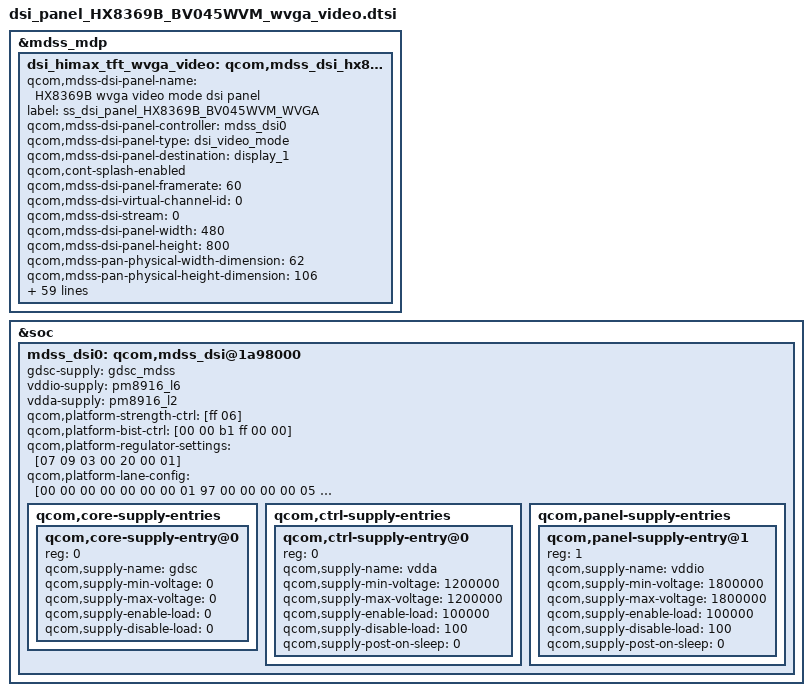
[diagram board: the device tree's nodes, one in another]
/* Copyright (c) 2013-14, Samsung Electronics Corporation. All rights reserved.
 *
 * This program is free software; you can redistribute it and/or modify
 * it under the terms of the GNU General Public License version 2 and
 * only version 2 as published by the Free Software Foundation.
 *
 * This program is distributed in the hope that it will be useful,
 * but WITHOUT ANY WARRANTY; without even the implied warranty of
 * MERCHANTABILITY or FITNESS FOR A PARTICULAR PURPOSE.  See the
 * GNU General Public License for more details.
 */

/*---------------------------------------------------------------------------
 * This file is autogenerated file using gcdb parser. Please do not edit it.
 * Update input XML file to add a new entry or update variable in this file
 * VERSION = "1.0"
 *---------------------------------------------------------------------------*/
&mdss_mdp {
	dsi_himax_tft_wvga_video: qcom,mdss_dsi_hx8369b_wvga_video {
		qcom,mdss-dsi-panel-name = "HX8369B wvga video mode dsi panel";
		label = "ss_dsi_panel_HX8369B_BV045WVM_WVGA";
		qcom,mdss-dsi-panel-controller = <&mdss_dsi0>;
		qcom,mdss-dsi-panel-type = "dsi_video_mode";
		qcom,mdss-dsi-panel-destination = "display_1";
		qcom,cont-splash-enabled;
		qcom,mdss-dsi-panel-framerate = <60>;
		qcom,mdss-dsi-virtual-channel-id = <0>;
		qcom,mdss-dsi-stream = <0>;
		qcom,mdss-dsi-panel-width = <480>;
		qcom,mdss-dsi-panel-height = <800>;
		qcom,mdss-pan-physical-width-dimension = <62>; /* <Width> real size of panel in mm */
		qcom,mdss-pan-physical-height-dimension = <106>; /*<Height> real size of panel in mm */
		qcom,mdss-dsi-lp11-init;
		qcom,mdss-dsi-init-delay-us = <100>;
		qcom,mdss-dsi-h-front-porch = <110>;
		qcom,mdss-dsi-h-back-porch = <110>;
		qcom,mdss-dsi-h-pulse-width = <4>;
		qcom,mdss-dsi-h-sync-skew = <0>;
		qcom,mdss-dsi-v-back-porch = <12>;
		qcom,mdss-dsi-v-front-porch = <10>;
		qcom,mdss-dsi-v-pulse-width = <4>;
		qcom,mdss-dsi-h-left-border = <0>;
		qcom,mdss-dsi-h-right-border = <0>;
		qcom,mdss-dsi-v-top-border = <0>;
		qcom,mdss-dsi-v-bottom-border = <0>;
		qcom,mdss-dsi-bpp = <24>;
		qcom,mdss-dsi-color-order = <0>;
		qcom,mdss-dsi-underflow-color = <0xff>;
		qcom,mdss-dsi-border-color = <0>;
		qcom,mdss-dsi-dma-trigger = "trigger_sw";
		qcom,mdss-dsi-mdp-trigger = "none";
		qcom,mdss-dsi-bl-min-level = <1>;
		qcom,mdss-dsi-bl-max-level = <255>;
		qcom,mdss-dsi-bl-pmic-control-type = "bl_ctrl_dcs";
		qcom,mdss-dsi-lane-0-state;
		qcom,mdss-dsi-lane-1-state;
		qcom,mdss-dsi-bllp-eof-power-mode;
		qcom,mdss-dsi-bllp-power-mode;
		qcom,mdss-dsi-traffic-mode = "burst_mode";
		qcom,mdss-force-clk-lane-hs = <0>;
		qcom,mdss-dsi-reset-sequence = <1 20>, <0 1>, <1 20>;
		qcom,mdss-dsi-h-sync-pulse = <0>;
		qcom,mdss-dsi-panel-timings = [51 14 0C 00 36 38 12 18 1B 03 04 00];
		qcom,mdss-dsi-t-clk-pre = <0x15>;
		qcom,mdss-dsi-t-clk-post = <0x04>;
		qcom,mdss-dsi-on-command = [
					/* < Power Setting Sequence(1) > */
					39 01 00 00 00 00 04 B9 FF 83 69
					39 01 00 00 00 00 0B B1 0B 83 77 00 0F 0F 0B 0B 0C 0A
					39 01 00 00 00 00 04 C6 41 FF 7D
					39 01 00 00 00 00 05 E3 00 00 00 00
					39 01 00 00 00 00 07 C0 73 50 00 34 C4 00
					/* < Power Setting Sequence(2) > */
					39 01 00 00 00 00 10 BA 31 00 16 CA B1 0A 00 10 28 02 21 21 9A 1A 8F
					39 01 00 00 00 00 02 3A 70
					39 01 00 00 00 00 05 B3 83 00 31 03
					39 01 00 00 00 00 02 B4 00
					39 01 00 00 00 00 02 CC 0E
					39 01 00 00 00 00 02 EA 72
					39 01 00 00 00 00 02 B2 03
					39 01 00 00 00 00 5D D5 00 00 07 00 09 00 00 10 01 00 00 00 01 42 37
										 00 00 08 2A 08 47 00 00 03 00 00 00 00 00 00 00
										 00 00 00 00 15 00 00 98 98 44 66 00 22 51 00 00
										 89 98 33 11 77 55 04 00 00 98 98 55 77 11 33 40
										 00 00 89 98 22 00 66 44 15 00 00 00 01 00 00 00
										 03 00 0F FF FF 03 00 0F FF FF 00 8C 5A
					/* < Gamma Setting Sequence(3) > */
					39 01 00 00 00 00 24 E0 01 02 05 2C 33 3F 10 33 06 0D 0E 10 16 10 14
										 13 19 01 02 05 2C 32 3F 0E 30 08 0E 0F 12 11 14
										 12 13 19 01
					/* < Display on Sequence> */
					39 01 00 00 00 00 03 C9 0F 01
					39 01 00 00 00 00 02 55 00
					39 01 00 00 00 00 02 53 24
					05 01 00 00 78 00 02 11 00
					05 01 00 00 0A 00 02 29 00
					];
		qcom,mdss-dsi-on-command-state = "dsi_lp_mode";
		qcom,mdss-dsi-off-command-state = "dsi_hs_mode";
		qcom,mdss-dsi-off-command = [39 01 00 10  00 02 28 00
					39 01 00 00 46 00 02 10 00];
		samsung,tft-common-support;
		samsung,panel-vendor = "BOE";
		samsung,mdss-dsi-bl-scale-low-level = <8>;
		samsung,mdss-dsi-bl-scale-dim-level = <8>;
		samsung,mdss-dsi-bl-scale-default-level = <89>;
		samsung,mdss-dsi-bl-scale-max-level = <188>;
		samsung,mdss-dsi-bl-pms-low-level = <7>;
		samsung,mdss-dsi-bl-pms-dim-level = <7>;
		samsung,mdss-dsi-bl-pms-default-level = <158>;
		samsung,mdss-dsi-bl-pms-max-level = <255>;
		samsung,tft_pwm_tx_cmds_revA=[
			39 01 00 00 00 00 02 51 FF/*First command should be PWM duty change command*/
		];
		samsung,cabc_on_tx_cmds_revA = [
			39 01 00 00 00 00 02 55 01
		];
		samsung,cabc_off_tx_cmds_revA = [
			39 01 00 00 00 00 02 55 00
		];
		/*
		* ************************************************************************************************************************
		* Scaled level to index mappings
		* ************************************************************************************************************************
		*/
		samsung,scaled_level_map_table_revA = <
		/*<idx>	  <from>  <till> <scaled_level> */
			0		0		7		8
			1		8		9		9
			2		10		12		10
			3		13		14		11
			4		15		17		12
			5		18		19		13
			6		20		22		14
			7		23		24		15
			8		25		27		16
			9		28		29		17
			10		30		32		18
			11		33		34		19
			12		35		37		20
			13		38		39		21
			14		40		42		23
			15		43		44		24
			16		45		47		25
			17		48		49		26
			18		50		52		27
			19		53		54		28
			20		55		57		30
			21		58		59		32
			22		60		62		34
			23		63		64		36
			24		65		67		38
			25		68		70		40
			26		71		72		42
			27		73		75		44
			28		76		77		46
			29		78		80		48
			30		81		82		50
			31		83		85		52
			32		86		87		54
			33		88		90		56
			34		91		92		58
			35		93		95		60
			36		96		97		61
			37		98		100		62
			38		101		102		63
			39		103		105		64
			40		106		107		65
			41		108		110		66
			42		111		112		67
			43		113		115		68
			44		116		117		69
			45		118		120		70
			46		121		122		71
			47		123		125		72
			48		126		127		73
			49		128		130		74
			50		131		133		75
			51		134		135		78
			52		136		138		79
			53		139		140		80
			54		141		143		81
			55		144		145		82
			56		146		148		83
			57		149		150		84
			58		151		153		85
			59		154		155		87
			60		156		158		89
			61		159		160		91
			62		161		163		93
			63		164		165		95
			64		166		168		97
			65		169		170		99
			66		171		173		101
			67		174		175		103
			68		176		178		105
			69		179		180		107
			70		182		183		109
			71		184		185		111
			72		186		188		113
			72		189		190		115
			74		191		193		117
			75		194		196		120
			76		197		198		123
			77		199		201		126
			78		202		203		129
			79		204		206		132
			80		207		208		135
			81		209		211		138
			82		212		213		141
			83		214		216		144
			84		217		218		147
			85		219		221		150
			86		222		223		153
			87		224		226		156
			88		227		228		159
			89		229		231		162
			90		232		233		165
			91		234		236		168
			92		237		238		171
			93		239		241		174
			94		242		243		177
			95		244		246		180
			96		247		248		183
			97		249		251		186
			98		252		253		187
			99		254		255		188
		>;
	};
};
&soc {
	mdss_dsi0: qcom,mdss_dsi@1a98000 {
		gdsc-supply = <&gdsc_mdss>;
		vddio-supply = <&pm8916_l6>;
		vdda-supply = <&pm8916_l2>;
		qcom,platform-strength-ctrl = [ff 06];
		qcom,platform-bist-ctrl = [00 00 b1 ff 00 00];
		qcom,platform-regulator-settings = [07 09 03 00 20 00 01];
		qcom,platform-lane-config = [00 00 00 00 00 00 00 01 97
			00 00 00 00 05 00 00 01 97
			00 00 00 00 0a 00 00 01 97
			00 00 00 00 0f 00 00 01 97
			00 c0 00 00 00 00 00 01 bb];
		qcom,core-supply-entries {
			#address-cells = <1>;
			#size-cells = <0>;

			qcom,core-supply-entry@0 {
				reg = <0>;
				qcom,supply-name = "gdsc";
				qcom,supply-min-voltage = <0>;
				qcom,supply-max-voltage = <0>;
				qcom,supply-enable-load = <0>;
				qcom,supply-disable-load = <0>;
			};
		};
		qcom,ctrl-supply-entries {
			#address-cells = <1>;
			#size-cells = <0>;

			qcom,ctrl-supply-entry@0 {
				reg = <0>;
				qcom,supply-name = "vdda";
				qcom,supply-min-voltage = <1200000>;
				qcom,supply-max-voltage = <1200000>;
				qcom,supply-enable-load = <100000>;
				qcom,supply-disable-load = <100>;
				qcom,supply-post-on-sleep = <0>;
			};
		};
		qcom,panel-supply-entries {
			#address-cells = <1>;
			#size-cells = <0>;

			qcom,panel-supply-entry@1 {
				reg = <1>;
				qcom,supply-name = "vddio";
				qcom,supply-min-voltage = <1800000>;
				qcom,supply-max-voltage = <1800000>;
				qcom,supply-enable-load = <100000>;
				qcom,supply-disable-load = <100>;
				qcom,supply-post-on-sleep = <0>;
			};
		};
	};
};

